# RK3399-AP register map
File version: 1
CPU: CA7 r0p1, little endian, MPU, FPU, I-cache, D-cache, VTOR, 4 interrupt priority bits, 0 interrupts
Registers are 32-bit, read-write, reset 0x0 unless marked. A register's access mark holds for its fields unless they carry their own. Offsets are from the block's base; [hi:lo] are bit positions; {n}, {i} and the like mark numbered series.

## DDRMON
Base 0xFF630000
0x00 DDRMON_IP_VERSION access not given — DDR Monitor IP Version
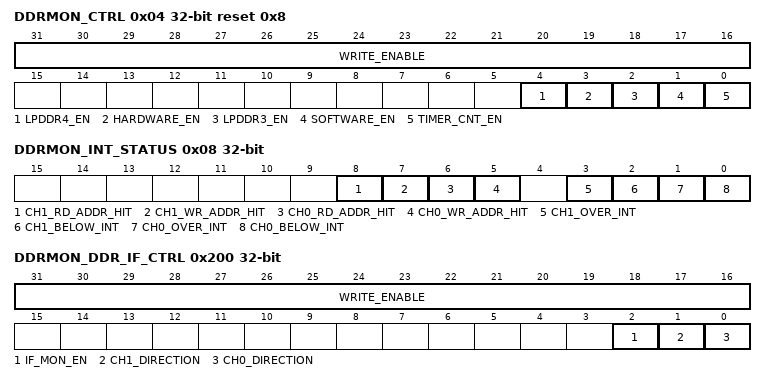
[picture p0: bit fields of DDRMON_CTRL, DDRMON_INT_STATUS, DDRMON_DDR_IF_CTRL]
0x04 DDRMON_CTRL reset 0x8 — DDR Monitor Control Register
  [31:16] WRITE_ENABLE — bit0~15 write enable When bit 16=1, bit 0 can be written by softwar . When bit 16=0, bit 0 cannot be written by software; When bit 17=1, bit 1 can be written by software. When bit 17=0, bit 1 cannot be written by software; ...... When bit 31=1, bit 15 can be written by software. When bit 31=0, bit 15 cannot be written by software;
  [4] LPDDR4_EN — LPDDR4 Mode Enable 1\'b1: enable 1\'b0: disable
  [3] HARDWARE_EN — Hardware Mode Enable 1\'b1: enable 1\'b0: disable
  [2] LPDDR3_EN — LPDDR3 Mode Monitor Enable 1\'b1: enable 1\'b0: disable
  [1] SOFTWARE_EN — Software Mode Enable 1\'b1: enable 1\'b0: disable
  [0] TIMER_CNT_EN — DFI Timer Count Enable 1\'b1: enable 1\'b0: disable
0x08 DDRMON_INT_STATUS ro — Interrupt Status
  [8] CH1_RD_ADDR_HIT — This is the interrupt status of channel 1 read address hit the setting range
  [7] CH1_WR_ADDR_HIT — This is the interrupt status of channel 1 write address hit the setting range
  [6] CH0_RD_ADDR_HIT — This is the interrupt status of channel 0 read address hit the setting range
  [5] CH0_WR_ADDR_HIT — This is the interrupt status of channel 0 write address hit the setting range
  [3] CH1_OVER_INT — This is the interrupt status of DDR read and write burst number more than high threshold in channel 0
  [2] CH1_BELOW_INT — This is the interrupt status of DDR read and write burst number less than low threshold in channel 0
  [1] CH0_OVER_INT — This is the interrupt status of DDR read and write burst number more than high threshold in channel 0
  [0] CH0_BELOW_INT — This is the interrupt status of DDR read and write burst number less than low threshold in channel 0
0x0C DDRMON_INT_MASK — Interrupt mask control
  [8:0] INT_MASK — Interrupt mask control, when bit set to 1\'b1, the corresponding interrupt will disable
0x10 DDRMON_TIMER_COUNT ro — The DFI Timer Threshold
  [31:0] TIMER_COUNT — The DFI timer threshold, the statistics of DDR access only be done when timer counter is less then this threshold in hardware mode
0x14 DDRMON_FLOOR_NUMBER ro — The Low Threshold in the Comparison of DDR Access
  [31:0] FLOOR_NUMBER — The low threshold in the comparison of DDR access
0x18 DDRMON_TOP_NUMBER ro — The High Threshold in the Comparison of DDR Access
  [31:0] TOP_NUMBER — The high threshold in the comparison of DDR access
0x1C DDRMON_CH0_DFI_ACT_NUM ro — Channel 0 DFI Active Command Number
  [31:0] CH0_DFI_ACT_NUM — DFI active command number in the statistics range of the channel 0
0x20 DDRMON_CH0_DFI_WR_NUM ro — Channel 0 DFI write Command Number
  [31:0] CH0_DFI_WR_NUM — DFI write command number in the statistics range of the channel 0
0x24 DDRMON_CH0_DFI_RD_NUM ro — Channel 0 DFI read Command Number
  [31:0] CH0_DFI_RD_NUM — DFI read command number in the statistics range of the channel 0
0x28 DDRMON_CH0_COUNT_NUM ro — Channel 0 Timer Count Number
  [31:0] CH0_DFI_COUNT_NUM — Timer count number in the statistics range of the channel 0, the value should be divided by 2 as actual timer count.
0x2C DDRMON_CH0_DFI_ACCESS_NUM ro — Channel 0 DFI Read and Write Command Number
  [31:0] CH0_DFI_ACCESS_NUM — DFI read and write command number in the statistics range of the channel 0
0x30 DDRMON_CH1_DFI_ACT_NUM ro — Channel 1 DFI Active Command Number
  [31:0] CH1_DFI_ACT_NUM — DFI active command number in the statistics range of the channel 1
0x34 DDRMON_CH1_DFI_WR_NUM ro — Channel 1 DFI write Command Number
  [31:0] CH1_DFI_WR_NUM — DFI write command number in the statistics range of the channel 1
0x38 DDRMON_CH1_DFI_RD_NUM ro — Channel 1 DFI read Command Number
  [31:0] CH1_DFI_RD_NUM — DFI read command number in the statistics range of the channel 1
0x3C DDRMON_CH1_COUNT_NUM ro — Channel 1 Timer Count Number
  [31:0] CH1_DFI_COUNT_NUM — Timer count number in the statistics range of the channel 1, the value should be divided by 2 as actual timer count.
0x40 DDRMON_CH1_DFI_ACCESS_NUM ro — Channel 1 DFI Read and Write Command Number
  [31:0] CH1_DFI_ACCESS_NUM — DFI read and write command number in the statistics range of the channel 1
0x200 DDRMON_DDR_IF_CTRL — DDR interface Control Register
  [31:16] WRITE_ENABLE — bit0~15 write enable When bit 16=1, bit 0 can be written by software. When bit 16=0, bit 0 cannot be written by software; When bit 17=1, bit 1 can be written by software. When bit 17=0, bit 1 cannot be written by software; ...... When bit 31=1, bit 15 can be written by software. When bit 31=0, bit 15 cannot be written by software;
  [2] IF_MON_EN — DDR interface and DFI monitor enable 1\'b1: enable 1\'b0: disable
  [1] CH1_DIRECTION — Write or read monitor in channel 1 for command statistics 1\'b1: read 1\'b0: write
  [0] CH0_DIRECTION — Write or read monitor in channel 0 for command statistics 1\'b1: read 1\'b0: write
0x20C DDRMON_CH0_WR_START_ADDR — Channel 0 Write Start Address
  [31:0] CH0_WR_START_ADDR — Channel 0 write start address for address comparison
0x210 DDRMON_CH0_WR_END_ADDR — Channel 0 Write End Address
  [31:0] CH0_WR_END_ADDR — Channel 0 write end address for address comparison
0x214 DDRMON_CH0_RD_START_ADDR — Channel 0 Read Start Address
  [31:0] CH0_RD_START_ADDR — Channel 0 read start address for address comparison
0x218 DDRMON_CH0_RD_END_ADDR — Channel 0 Read End Address
  [31:0] CH0_RD_END_ADDR — Channel 0 read end address for address comparison
0x224 DDRMON_CH1_WR_START_ADDR — Channel 1 Write Start Address
  [31:0] CH1_WR_START_ADDR — Channel 1 write start address for address comparison
0x228 DDRMON_CH1_WR_END_ADDR — Channel 1 Write End Address
  [31:0] CH1_WR_END_ADDR — Channel 1 write end address for address comparison
0x22C DDRMON_CH1_RD_START_ADDR — Channel 1 Read Start Address
  [31:0] CH1_RD_START_ADDR — Channel 1 read start address for address comparison
0x230 DDRMON_CH1_RD_END_ADDR — Channel 1 Read End Address
  [31:0] CH1_RD_END_ADDR — Channel 1 read end address for address comparison
{0x240+8i} DDRMON_CH0_DDR_FIFO{i}_ADDR ro (i=0..3) — DDR Channel 0 Controller Interface Address FIFO{i}
  [31:0] CH0_DDR_FIFO{i}_ADDR — Channel 0 DDR controller interface address FIFO{i}
{0x260+8i} DDRMON_CH1_DDR_FIFO{i}_ADDR ro (i=0..3) — DDR Channel 1 Controller Interface Address FIFO{i}
  [31:0] CH1_DDR_FIFO{i}_ADDR — Channel 1 DDR controller interface address FIFO{i}
